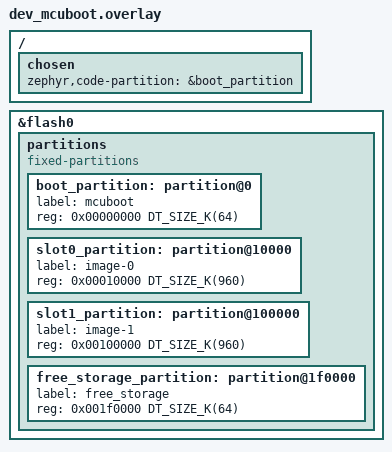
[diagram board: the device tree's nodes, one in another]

&flash0 {
    partitions {

        /delete-node/ partition@0;
        /delete-node/ partition@10000;
        /delete-node/ partition@78000;
        /delete-node/ partition@e0000;
        /delete-node/ partition@f0000;

        compatible = "fixed-partitions";
        #address-cells = <1>;
        #size-cells = <1>;

        /* Bank 1: 0x08000000 - 0x080FFFFF */
        boot_partition: partition@0 {
            label = "mcuboot";
            reg = <0x00000000 DT_SIZE_K(64)>;
        };

        slot0_partition: partition@10000 {
            label = "image-0";
            reg = <0x00010000 DT_SIZE_K(960)>; // 1024K - 64K
        };

        /* Bank 2: 0x08100000 - 0x081FFFFF */
        slot1_partition: partition@100000 {
            label = "image-1";
            reg = <0x00100000 DT_SIZE_K(960)>; // 1024K - 64K
        };

        free_storage_partition: partition@1f0000 {
            label = "free_storage";
            reg = <0x001f0000 DT_SIZE_K(64)>;
        };
    };
};

/ {
    chosen {
        zephyr,code-partition = &boot_partition;
    };
};
